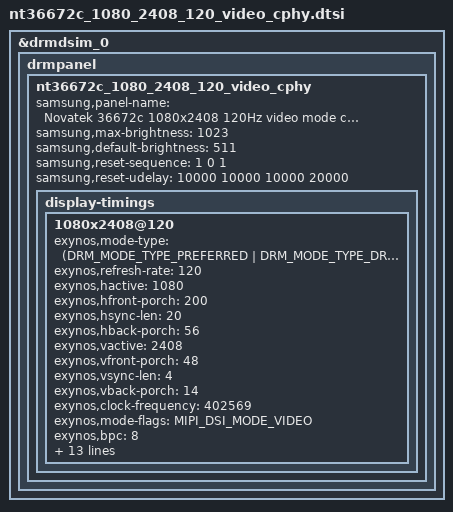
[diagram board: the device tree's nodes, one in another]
#include <dt-bindings/display/exynos-display.h>
#include <dt-bindings/display/exynos-mipi-display.h>

&drmdsim_0 {
	drmpanel {
		nt36672c_1080_2408_120_video_cphy: nt36672c_1080_2408_120_video_cphy {
			samsung,panel-name = "Novatek 36672c 1080x2408 120Hz video mode cphy panel";

			samsung,max-brightness = <1023>;
			samsung,default-brightness = <511>;

			samsung,reset-sequence = <1 0 1>;
			samsung,reset-udelay = <10000 10000 10000 20000>;

			display-timings {
				1080x2408@120 {
					exynos,mode-type = <(DRM_MODE_TYPE_PREFERRED |
							DRM_MODE_TYPE_DRIVER)>;
					exynos,refresh-rate = <120>;
					exynos,hactive = <1080>;
					exynos,hfront-porch = <200>;
					exynos,hsync-len = <20>;
					exynos,hback-porch = <56>;
					exynos,vactive = <2408>;
					exynos,vfront-porch = <48>;
					exynos,vsync-len = <4>;
					exynos,vback-porch = <14>;
					exynos,clock-frequency = <402569>;

					exynos,mode-flags = <MIPI_DSI_MODE_VIDEO>;
					exynos,bpc = <8>;
					exynos,lp-mode = <0>;
					exynos,dsc-en = <1>;
					exynos,dsc-count = <1>;
					exynos,dsc-slice-count = <2>;
					exynos,dsc-slice-height = <8>;

					exynos,pre-pps-cmds = <
						0x02 0xFF 0x10 0x00
						>;

					exynos,pps-cmds = <
						0x58
						0x11 0x00 0x00 0x89 0x30 0x80 0x09 0x68
						0x04 0x38 0x00 0x08 0x02 0x1C 0x02 0x1C
						0x00 0xAA 0x02 0x0E 0x00 0x20 0x00 0x2B
						0x00 0x07 0x00 0x0C 0x0D 0xB7 0x0C 0xB7
						0x18 0x00 0x1B 0xA0 0x03 0x0C 0x20 0x00
						0x06 0x0B 0x0B 0x33 0x0E 0x1C 0x2A 0x38
						0x46 0x54 0x62 0x69 0x70 0x77 0x79 0x7B
						0x7D 0x7E 0x01 0x02 0x01 0x00 0x09 0x40
						0x09 0xBE 0x19 0xFC 0x19 0xFA 0x19 0xF8
						0x1A 0x38 0x1A 0x78 0x1A 0xB6 0x2A 0xF6
						0x2B 0x34 0x2B 0x74 0x3B 0x74 0x6B 0xF4
						0x00
						>;

					exynos,on-cmds = <
						0x02 0xFF 0x10 0x00
						0x02 0x51 0xFF 0x00
						0x02 0x53 0x24 0x00
						0x02 0xFF 0x10 0x00
						0x02 0xFB 0x01 0x00
						0x06 0x3B 0x03 0x12 0x30 0x04 0x04 0x00
						0x02 0xB0 0x00 0x00
						0x02 0xC0 0x03 0x00
						0x11 0xC1 0x89 0x28 0x00 0x08 0x00 0xAA 0x02 0x0E 0x00 0x2B 0x00 0x07 0x0D 0xB7 0x0C 0xB7 0x00
						0x03 0xC2 0x1B 0xA0 0x10
						0x02 0xFF 0x25 0x00
						0x02 0xFB 0x01 0x00
						0x02 0x18 0x20 0x00
						0x02 0xFF 0xE0 0x00
						0x02 0xFB 0x01 0x00
						0x03 0x35 0x82 0x00 0x00
						0x02 0xFF 0xF0 0x00
						0x02 0xFB 0x01 0x00
						0x02 0x5A 0x00 0x00
						0x02 0xFF 0xD0 0x00
						0x02 0xFB 0x01 0x00
						0x02 0x53 0x22 0x00
						0x02 0x54 0x02 0x00
						0x02 0xFF 0x10 0x00
						>;
					exynos,disp-on-cmds = <
						0x01 0x11 0x78
						0x01 0x29 0x32
						>;
					exynos,off-cmds = <
						0x01 0x10 0x00
						0x01 0x28 0x00
						>;
				};
			};
		};
	};
};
